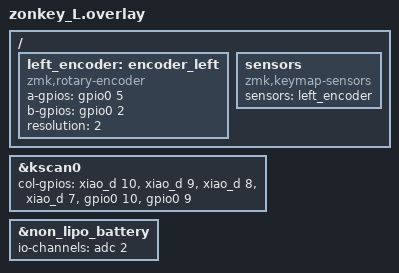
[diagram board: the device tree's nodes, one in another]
#include "zonkey.dtsi"


&kscan0 {
    col-gpios
        = <&xiao_d 10 GPIO_ACTIVE_HIGH>
        , <&xiao_d 9 GPIO_ACTIVE_HIGH> 
        , <&xiao_d 8 GPIO_ACTIVE_HIGH> 
        , <&xiao_d 7 GPIO_ACTIVE_HIGH> 
        , <&gpio0 10 GPIO_ACTIVE_HIGH>
        , <&gpio0 9 GPIO_ACTIVE_HIGH>
        ;
};


/ {
    left_encoder: encoder_left {
    compatible = "zmk,rotary-encoder";

    a-gpios = <&gpio0 5 GPIO_ACTIVE_HIGH>;
    b-gpios = <&gpio0 2 GPIO_ACTIVE_HIGH>;

    resolution = <2>;
};
};

/ {
    sensors {
        compatible = "zmk,keymap-sensors";
        sensors = <&left_encoder>;
    };
};

&non_lipo_battery {
    io-channels = <&adc 2>;
};
